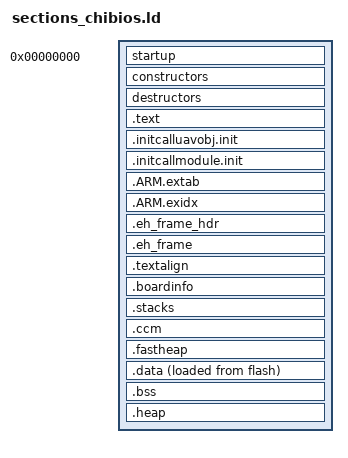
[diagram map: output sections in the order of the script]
/*
    ChibiOS/RT - Copyright (C) 2006,2007,2008,2009,2010,
                 2011,2012,2013 Giovanni Di Sirio.

    This file is part of ChibiOS/RT.

    ChibiOS/RT is free software; you can redistribute it and/or modify
    it under the terms of the GNU General Public License as published by
    the Free Software Foundation; either version 3 of the License, or
    (at your option) any later version.

    ChibiOS/RT is distributed in the hope that it will be useful,
    but WITHOUT ANY WARRANTY; without even the implied warranty of
    MERCHANTABILITY or FITNESS FOR A PARTICULAR PURPOSE.  See the
    GNU General Public License for more details.

    You should have received a copy of the GNU General Public License
    along with this program.  If not, see <http://www.gnu.org/licenses/>.

                                      ---

    A special exception to the GPL can be applied should you wish to distribute
    a combined work that includes ChibiOS/RT, without being obliged to provide
    the source code for any proprietary components. See the file exception.txt
    for full details of how and when the exception can be applied.
*/

__ram_start__           = ORIGIN(ram);
__ram_size__            = LENGTH(ram);
__ram_end__             = __ram_start__ + __ram_size__;

ENTRY(ResetHandler)

SECTIONS
{
    . = 0;
    _text = .;

    startup : ALIGN(16) SUBALIGN(16)
    {
        PROVIDE (pios_isr_vector_table_base = .);
        KEEP(*(vectors))
    } > flash

    constructors : ALIGN(4) SUBALIGN(4)
    {
        PROVIDE(__init_array_start = .);
        KEEP(*(SORT(.init_array.*)))
        KEEP(*(.init_array))
        PROVIDE(__init_array_end = .);
    } > flash

    destructors : ALIGN(4) SUBALIGN(4)
    {
        PROVIDE(__fini_array_start = .);
        KEEP(*(.fini_array))
        KEEP(*(SORT(.fini_array.*)))
        PROVIDE(__fini_array_end = .);
    } > flash

    .text : ALIGN(16) SUBALIGN(16)
    {
        *(.text.startup.*)
        *(.text)
        *(.text.*)
        *(.rodata)
        *(.rodata.*)
        *(.glue_7t)
        *(.glue_7)
        *(.gcc*)
    } > flash

    /* 
     * Init section for UAVObjects.
     */
    .initcalluavobj.init :
    {
        . = ALIGN(4);
        __uavobj_initcall_start = .;
        KEEP(*(.initcalluavobj.init))
        . = ALIGN(4);
        __uavobj_initcall_end   = .;
    } > flash

    /* 
     * Module init section section
     */
    .initcallmodule.init :
    {
        . = ALIGN(4);
        __module_initcall_start = .;
        KEEP(*(.initcallmodule.init))
        . = ALIGN(4);
        __module_initcall_end   = .;
    } > flash

    .ARM.extab :
    {
        *(.ARM.extab* .gnu.linkonce.armextab.*)
    } > flash

    .ARM.exidx : {
        PROVIDE(__exidx_start = .);
        *(.ARM.exidx* .gnu.linkonce.armexidx.*)
        PROVIDE(__exidx_end = .);
     } > flash

    .eh_frame_hdr :
    {
        *(.eh_frame_hdr)
    } > flash

    .eh_frame : ONLY_IF_RO
    {
        *(.eh_frame)
    } > flash
    
    .textalign : ONLY_IF_RO
    {
        . = ALIGN(8);
    } > flash

    . = ALIGN(4);
    _etext = .;
    _textdata = _etext;
    
    /*
     * Board info structure, normally only generated by the bootloader but can
     * be read by the application.
     */
    PROVIDE(pios_board_info_blob = ORIGIN(bd_info));
    .boardinfo :
    {
        . = ALIGN(4);
        KEEP(*(.boardinfo))
        . = ALIGN(ORIGIN(bd_info)+LENGTH(bd_info));
    } > bd_info

    .stacks :
    {
        . = ALIGN(8);
        __main_stack_base__ = .;
        . += __main_stack_size__;
        . = ALIGN(8);
        __main_stack_end__ = .;
        __process_stack_base__ = .;
        __main_thread_stack_base__ = .;
        . += __process_stack_size__;
        . = ALIGN(8);
        __process_stack_end__ = .;
        __main_thread_stack_end__ = .;
    } > ccmram

    .ccm :
    {
        PROVIDE(_cmm_start = .);
        . = ALIGN(4);
        *(.bss.mainthread.*)
        . = ALIGN(4);
        *(.bss._idle_thread_wa)
        . = ALIGN(4);
        *(.bss.rlist)
        . = ALIGN(4);
        *(.bss.vtlist)
        . = ALIGN(4);
        *(.bss.endmem)
        . = ALIGN(4);
        *(.bss.nextmem)
        . = ALIGN(4);
        *(.bss.default_heap)
        . = ALIGN(4);
        PROVIDE(_cmm_end = .);
    } > ccmram

    /*
     * The fastheap consumes the remainder of the CCSRAM.
     */
    .fastheap (NOLOAD) :
    {
        . = ALIGN(4);
        _sfastheap = . ;
        
        /*
         * This allows us to declare an object or objects up to the minimum acceptable
         * heap size and receive a linker error if the space available for the heap is
         * not sufficient.
         */
        *(.fastheap)
        
        /* extend the heap up to the top of SRAM */
        . = ORIGIN(ccmram) + LENGTH(ccmram) - ABSOLUTE(_sfastheap);
        _efastheap = .;
    } > ccmram

    .data :
    {
        . = ALIGN(4);
        PROVIDE(_data = .);
        *(.data)
        . = ALIGN(4);
        *(.data.*)
        . = ALIGN(4);
        *(.ramtext)
        . = ALIGN(4);
        PROVIDE(_edata = .);
    } > ram AT > flash

    .bss :
    {
        . = ALIGN(4);
        PROVIDE(_bss_start = .);
        *(.bss)
        . = ALIGN(4);
        *(.bss.*)
        . = ALIGN(4);
        *(COMMON)
        . = ALIGN(4);
        PROVIDE(_bss_end = .);
    } > ram

    /*
     * The heap consumes the remainder of the SRAM.
     */
    .heap (NOLOAD) :
    {
        . = ALIGN(4);
        _sheap = . ;
        
        /*
         * This allows us to declare an object or objects up to the minimum acceptable
         * heap size and receive a linker error if the space available for the heap is
         * not sufficient.
         */
        *(.heap)
        
        /* extend the heap up to the top of SRAM */
        . = ORIGIN(ram) + LENGTH(ram) - ABSOLUTE(_sheap);
        _eheap = .;
    } > ram
}

PROVIDE(end = .);
_end            = .;

__heap_base__   = _end;
__heap_end__    = __ram_end__;
